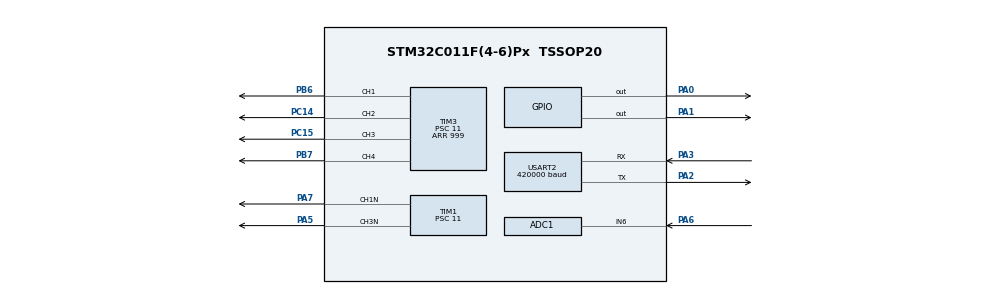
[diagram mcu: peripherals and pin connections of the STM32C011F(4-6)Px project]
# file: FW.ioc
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ADC1.NbrOfConversionFlag=0
ADC1.SamplingTimeCommon1=ADC_SAMPLETIME_12CYCLES_5
ADC1.SelectedChannel=ADC_CHANNEL_6
ADC1.master=1
Mcu.Family=STM32C0
Mcu.Name=STM32C011F(4-6)Px
Mcu.Package=TSSOP20
NVIC.USART2_IRQn=true\:0\:0\:false\:false\:true\:true\:true\:true
PA0.Signal=GPIO_Output
PA1.Signal=GPIO_Output
PA13.Mode=Serial_Wire
PA13.Signal=DEBUG_SWDIO
PA14-BOOT0.Mode=Serial_Wire
PA14-BOOT0.Signal=DEBUG_SWCLK
PA2.Mode=Asynchronous
PA2.Signal=USART2_TX
PA3.Mode=Asynchronous
PA3.Signal=USART2_RX
PA5.Mode=PWM Generation3 CH3N
PA5.Signal=TIM1_CH3N
PA6.Mode=IN6
PA6.Signal=ADC1_IN6
PA7.Mode=PWM Generation1 CH1N
PA7.Signal=TIM1_CH1N
PB6.Signal=S_TIM3_CH1
PB7.Signal=S_TIM3_CH4
PC14-OSCX_IN\ (PC14).Signal=S_TIM3_CH2
PC15-OSCX_OUT\ (PC15).Signal=S_TIM3_CH3
PF2-NRST.Signal=S_TIM1_CH4
ProjectManager.HeapSize=0x200
ProjectManager.StackSize=0x400
ProjectManager.TargetToolchain=STM32CubeIDE
RCC.ADCFreq_Value=48000000
RCC.AHBFreq_Value=48000000
RCC.CortexFreq_Value=48000000
RCC.EXTERNAL_CLOCK_VALUE=12288000
RCC.HCLKFreq_Value=48000000
RCC.HSE_VALUE=8000000
RCC.HSISYSCLKDivider=RCC_HSI_DIV1
RCC.HSI_VALUE=48000000
RCC.LSE_VALUE=32768
RCC.SYSCLKFreq_VALUE=48000000
SH.S_TIM1_CH4.0=TIM1_CH4
SH.S_TIM3_CH1.0=TIM3_CH1,PWM Generation1 CH1
SH.S_TIM3_CH2.0=TIM3_CH2,PWM Generation2 CH2
SH.S_TIM3_CH3.0=TIM3_CH3,PWM Generation3 CH3
SH.S_TIM3_CH4.0=TIM3_CH4,PWM Generation4 CH4
TIM1.Channel-PWM\ Generation1\ CH1N=TIM_CHANNEL_1
TIM1.Channel-PWM\ Generation3\ CH3N=TIM_CHANNEL_3
TIM1.Period=999
TIM1.Prescaler=11
TIM3.Channel-PWM\ Generation1\ CH1=TIM_CHANNEL_1
TIM3.Channel-PWM\ Generation2\ CH2=TIM_CHANNEL_2
TIM3.Channel-PWM\ Generation3\ CH3=TIM_CHANNEL_3
TIM3.Channel-PWM\ Generation4\ CH4=TIM_CHANNEL_4
TIM3.Period=999
TIM3.Prescaler=11
USART2.BaudRate=420000
USART2.DMADisableonRxErrorParam=ADVFEATURE_DMA_DISABLEONRXERROR
USART2.OverrunDisableParam=ADVFEATURE_OVERRUN_DISABLE
USART2.VirtualMode-Asynchronous=VM_ASYNC
VP_CRC_VS_CRC.Mode=CRC_Activate
VP_SYS_VS_PINREMAP.Mode=PINREMAP
VP_SYS_VS_PINREMAP_10_12.Mode=PINREMAP_10_12
VP_TIM1_VS_ClockSourceINT.Mode=Internal
VP_TIM3_VS_ClockSourceINT.Mode=Internal
board=custom

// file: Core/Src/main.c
/* USER CODE BEGIN Header */
/**
  ******************************************************************************
  * @file           : main.c
  * @brief          : Main program body
  ******************************************************************************
  * @attention
  *
  * Copyright (c) 2026 STMicroelectronics.
  * All rights reserved.
  *
  * This software is licensed under terms that can be found in the LICENSE file
  * in the root directory of this software component.
  * If no LICENSE file comes with this software, it is provided AS-IS.
  *
  ******************************************************************************
  */
/* USER CODE END Header */
#include "main.h"

/* USER CODE BEGIN Includes */
#include "crsf_esc.h"
/* USER CODE END Includes */

void SystemClock_Config(void);
static void MX_GPIO_Init(void);
static void MX_TIM1_Init(void);
static void MX_TIM3_Init(void);
static void MX_USART2_UART_Init(void);
static void MX_ADC1_Init(void);
static void MX_CRC_Init(void);

int main(void)
{

  /* MCU Configuration--------------------------------------------------------*/

  /* Reset of all peripherals, Initializes the Flash interface and the Systick. */
  LL_APB2_GRP1_EnableClock(LL_APB2_GRP1_PERIPH_SYSCFG);
  LL_APB1_GRP1_EnableClock(LL_APB1_GRP1_PERIPH_PWR);

  /* SysTick_IRQn interrupt configuration */
  NVIC_SetPriority(SysTick_IRQn, 3);

  LL_SYSCFG_EnablePinRemap(LL_SYSCFG_PIN_RMP_PA11);
  LL_SYSCFG_EnablePinRemap(LL_SYSCFG_PIN_RMP_PA12);

  /* Configure the system clock */
  SystemClock_Config();

  /* Initialize all configured peripherals */
  MX_GPIO_Init();
  MX_TIM1_Init();
  MX_TIM3_Init();
  MX_USART2_UART_Init();
  MX_ADC1_Init();
  MX_CRC_Init();
  /* USER CODE BEGIN 2 */
  esc_main();
  /* USER CODE END 2 */

  /* Infinite loop */
  while (1)
  {

  }
}

void SystemClock_Config(void)
{

  LL_FLASH_SetLatency(LL_FLASH_LATENCY_1);

  /* HSI configuration and activation */
  LL_RCC_HSI_Enable();
  while(LL_RCC_HSI_IsReady() != 1)
  {
  }

  LL_RCC_HSI_SetCalibTrimming(64);
  LL_RCC_SetHSIDiv(LL_RCC_HSI_DIV_1);
  /* Set AHB prescaler*/
  LL_RCC_SetAHBPrescaler(LL_RCC_HCLK_DIV_1);

  /* Sysclk activation on the HSI */
  LL_RCC_SetSysClkSource(LL_RCC_SYS_CLKSOURCE_HSI);
  while(LL_RCC_GetSysClkSource() != LL_RCC_SYS_CLKSOURCE_STATUS_HSI)
  {
  }

  /* Set APB1 prescaler*/
  LL_RCC_SetAPB1Prescaler(LL_RCC_APB1_DIV_1);
  LL_Init1msTick(48000000);
  /* Update CMSIS variable (which can be updated also through SystemCoreClockUpdate function) */
  LL_SetSystemCoreClock(48000000);
}

static void MX_ADC1_Init(void)
{

  LL_ADC_InitTypeDef ADC_InitStruct = {0};
  LL_ADC_REG_InitTypeDef ADC_REG_InitStruct = {0};

  LL_GPIO_InitTypeDef GPIO_InitStruct = {0};

  LL_RCC_SetADCClockSource(LL_RCC_ADC_CLKSOURCE_SYSCLK);

  /* Peripheral clock enable */
  LL_APB2_GRP1_EnableClock(LL_APB2_GRP1_PERIPH_ADC);

  LL_IOP_GRP1_EnableClock(LL_IOP_GRP1_PERIPH_GPIOA);
  /**ADC1 GPIO Configuration
  PA6   ------> ADC1_IN6
  */
  GPIO_InitStruct.Pin = LL_GPIO_PIN_6;
  GPIO_InitStruct.Mode = LL_GPIO_MODE_ANALOG;
  GPIO_InitStruct.Pull = LL_GPIO_PULL_NO;
  LL_GPIO_Init(GPIOA, &GPIO_InitStruct);

  /** Configure the global features of the ADC (Clock, Resolution, Data Alignment and number of conversion)
  */

   #define ADC_CHANNEL_CONF_RDY_TIMEOUT_MS ( 1U)
   #if (USE_TIMEOUT == 1)
   uint32_t Timeout ; /* Variable used for Timeout management */
   #endif /* USE_TIMEOUT */

  ADC_InitStruct.Clock = LL_ADC_CLOCK_SYNC_PCLK_DIV2;
  ADC_InitStruct.Resolution = LL_ADC_RESOLUTION_12B;
  ADC_InitStruct.DataAlignment = LL_ADC_DATA_ALIGN_RIGHT;
  ADC_InitStruct.LowPowerMode = LL_ADC_LP_MODE_NONE;
  LL_ADC_Init(ADC1, &ADC_InitStruct);
  LL_ADC_REG_SetSequencerConfigurable(ADC1, LL_ADC_REG_SEQ_FIXED);
  ADC_REG_InitStruct.TriggerSource = LL_ADC_REG_TRIG_SOFTWARE;
  ADC_REG_InitStruct.SequencerLength = LL_ADC_REG_SEQ_SCAN_DISABLE;
  ADC_REG_InitStruct.SequencerDiscont = LL_ADC_REG_SEQ_DISCONT_DISABLE;
  ADC_REG_InitStruct.ContinuousMode = LL_ADC_REG_CONV_SINGLE;
  ADC_REG_InitStruct.DMATransfer = LL_ADC_REG_DMA_TRANSFER_NONE;
  ADC_REG_InitStruct.Overrun = LL_ADC_REG_OVR_DATA_PRESERVED;
  LL_ADC_REG_Init(ADC1, &ADC_REG_InitStruct);
  LL_ADC_REG_SetSequencerScanDirection(ADC1, LL_ADC_REG_SEQ_SCAN_DIR_FORWARD);
  LL_ADC_SetOverSamplingScope(ADC1, LL_ADC_OVS_DISABLE);
  LL_ADC_SetTriggerFrequencyMode(ADC1, LL_ADC_CLOCK_FREQ_MODE_HIGH);
  LL_ADC_REG_SetSequencerChAdd(ADC1, LL_ADC_CHANNEL_6);

   /* Poll for ADC channel configuration ready */
   #if (USE_TIMEOUT == 1)
   Timeout = ADC_CHANNEL_CONF_RDY_TIMEOUT_MS;
   #endif /* USE_TIMEOUT */
   while (LL_ADC_IsActiveFlag_CCRDY(ADC1) == 0)
     {
   #if (USE_TIMEOUT == 1)
   /* Check Systick counter flag to decrement the time-out value */
   if (LL_SYSTICK_IsActiveCounterFlag())
     {
   if(Timeout-- == 0)
         {
   Error_Handler();
         }
     }
   #endif /* USE_TIMEOUT */
     }
   /* Clear flag ADC channel configuration ready */
   LL_ADC_ClearFlag_CCRDY(ADC1);
  LL_ADC_SetSamplingTimeCommonChannels(ADC1, LL_ADC_SAMPLINGTIME_COMMON_1, LL_ADC_SAMPLINGTIME_12CYCLES_5);
  LL_ADC_DisableIT_EOC(ADC1);
  LL_ADC_DisableIT_EOS(ADC1);

   /* Enable ADC internal voltage regulator */
   LL_ADC_EnableInternalRegulator(ADC1);
   /* Delay for ADC internal voltage regulator stabilization. */
   /* Compute number of CPU cycles to wait for, from delay in us. */
   /* Note: Variable divided by 2 to compensate partially */
   /* CPU processing cycles (depends on compilation optimization). */
   /* Note: If system core clock frequency is below 200kHz, wait time */
   /* is only a few CPU processing cycles. */
   uint32_t wait_loop_index;
   wait_loop_index = ((LL_ADC_DELAY_INTERNAL_REGUL_STAB_US * (SystemCoreClock / (100000 * 2))) / 10);
   while(wait_loop_index != 0)
     {
   wait_loop_index--;
     }

}

static void MX_CRC_Init(void)
{

  /* Peripheral clock enable */
  LL_AHB1_GRP1_EnableClock(LL_AHB1_GRP1_PERIPH_CRC);

  LL_CRC_SetInputDataReverseMode(CRC, LL_CRC_INDATA_REVERSE_NONE);
  LL_CRC_SetOutputDataReverseMode(CRC, LL_CRC_OUTDATA_REVERSE_NONE);
  LL_CRC_SetPolynomialCoef(CRC, LL_CRC_DEFAULT_CRC32_POLY);
  LL_CRC_SetPolynomialSize(CRC, LL_CRC_POLYLENGTH_32B);
  LL_CRC_SetInitialData(CRC, LL_CRC_DEFAULT_CRC_INITVALUE);

}

static void MX_TIM1_Init(void)
{

  LL_TIM_InitTypeDef TIM_InitStruct = {0};
  LL_TIM_OC_InitTypeDef TIM_OC_InitStruct = {0};
  LL_TIM_BDTR_InitTypeDef TIM_BDTRInitStruct = {0};

  LL_GPIO_InitTypeDef GPIO_InitStruct = {0};

  /* Peripheral clock enable */
  LL_APB2_GRP1_EnableClock(LL_APB2_GRP1_PERIPH_TIM1);

  LL_IOP_GRP1_EnableClock(LL_IOP_GRP1_PERIPH_GPIOF);
  /**TIM1 GPIO Configuration
  PF2-NRST   ------> TIM1_CH4
  */
  GPIO_InitStruct.Pin = LL_GPIO_PIN_2;
  GPIO_InitStruct.Mode = LL_GPIO_MODE_ALTERNATE;
  GPIO_InitStruct.Speed = LL_GPIO_SPEED_FREQ_LOW;
  GPIO_InitStruct.OutputType = LL_GPIO_OUTPUT_PUSHPULL;
  GPIO_InitStruct.Pull = LL_GPIO_PULL_NO;
  GPIO_InitStruct.Alternate = LL_GPIO_AF_1;
  LL_GPIO_Init(GPIOF, &GPIO_InitStruct);

  TIM_InitStruct.Prescaler = 11;
  TIM_InitStruct.CounterMode = LL_TIM_COUNTERMODE_UP;
  TIM_InitStruct.Autoreload = 999;
  TIM_InitStruct.ClockDivision = LL_TIM_CLOCKDIVISION_DIV1;
  TIM_InitStruct.RepetitionCounter = 0;
  LL_TIM_Init(TIM1, &TIM_InitStruct);
  LL_TIM_DisableARRPreload(TIM1);
  LL_TIM_SetClockSource(TIM1, LL_TIM_CLOCKSOURCE_INTERNAL);
  LL_TIM_OC_EnablePreload(TIM1, LL_TIM_CHANNEL_CH1);
  TIM_OC_InitStruct.OCMode = LL_TIM_OCMODE_PWM1;
  TIM_OC_InitStruct.OCState = LL_TIM_OCSTATE_DISABLE;
  TIM_OC_InitStruct.OCNState = LL_TIM_OCSTATE_DISABLE;
  TIM_OC_InitStruct.CompareValue = 0;
  TIM_OC_InitStruct.OCPolarity = LL_TIM_OCPOLARITY_HIGH;
  TIM_OC_InitStruct.OCNPolarity = LL_TIM_OCPOLARITY_HIGH;
  TIM_OC_InitStruct.OCIdleState = LL_TIM_OCIDLESTATE_LOW;
  TIM_OC_InitStruct.OCNIdleState = LL_TIM_OCIDLESTATE_LOW;
  LL_TIM_OC_Init(TIM1, LL_TIM_CHANNEL_CH1, &TIM_OC_InitStruct);
  LL_TIM_OC_DisableFast(TIM1, LL_TIM_CHANNEL_CH1);
  LL_TIM_OC_EnablePreload(TIM1, LL_TIM_CHANNEL_CH3);
  LL_TIM_OC_Init(TIM1, LL_TIM_CHANNEL_CH3, &TIM_OC_InitStruct);
  LL_TIM_OC_DisableFast(TIM1, LL_TIM_CHANNEL_CH3);
  LL_TIM_SetTriggerOutput(TIM1, LL_TIM_TRGO_RESET);
  LL_TIM_SetTriggerOutput2(TIM1, LL_TIM_TRGO2_RESET);
  LL_TIM_DisableMasterSlaveMode(TIM1);
  TIM_BDTRInitStruct.OSSRState = LL_TIM_OSSR_DISABLE;
  TIM_BDTRInitStruct.OSSIState = LL_TIM_OSSI_DISABLE;
  TIM_BDTRInitStruct.LockLevel = LL_TIM_LOCKLEVEL_OFF;
  TIM_BDTRInitStruct.DeadTime = 0;
  TIM_BDTRInitStruct.BreakState = LL_TIM_BREAK_DISABLE;
  TIM_BDTRInitStruct.BreakPolarity = LL_TIM_BREAK_POLARITY_HIGH;
  TIM_BDTRInitStruct.BreakFilter = LL_TIM_BREAK_FILTER_FDIV1;
  TIM_BDTRInitStruct.BreakAFMode = LL_TIM_BREAK_AFMODE_INPUT;
  TIM_BDTRInitStruct.Break2State = LL_TIM_BREAK2_DISABLE;
  TIM_BDTRInitStruct.Break2Polarity = LL_TIM_BREAK2_POLARITY_HIGH;
  TIM_BDTRInitStruct.Break2Filter = LL_TIM_BREAK2_FILTER_FDIV1;
  TIM_BDTRInitStruct.Break2AFMode = LL_TIM_BREAK_AFMODE_INPUT;
  TIM_BDTRInitStruct.AutomaticOutput = LL_TIM_AUTOMATICOUTPUT_DISABLE;
  LL_TIM_BDTR_Init(TIM1, &TIM_BDTRInitStruct);
  LL_IOP_GRP1_EnableClock(LL_IOP_GRP1_PERIPH_GPIOA);
  /**TIM1 GPIO Configuration
  PA5   ------> TIM1_CH3N
  PA7   ------> TIM1_CH1N
  */
  GPIO_InitStruct.Pin = LL_GPIO_PIN_5;
  GPIO_InitStruct.Mode = LL_GPIO_MODE_ALTERNATE;
  GPIO_InitStruct.Speed = LL_GPIO_SPEED_FREQ_LOW;
  GPIO_InitStruct.OutputType = LL_GPIO_OUTPUT_PUSHPULL;
  GPIO_InitStruct.Pull = LL_GPIO_PULL_NO;
  GPIO_InitStruct.Alternate = LL_GPIO_AF_2;
  LL_GPIO_Init(GPIOA, &GPIO_InitStruct);

  GPIO_InitStruct.Pin = LL_GPIO_PIN_7;
  GPIO_InitStruct.Mode = LL_GPIO_MODE_ALTERNATE;
  GPIO_InitStruct.Speed = LL_GPIO_SPEED_FREQ_LOW;
  GPIO_InitStruct.OutputType = LL_GPIO_OUTPUT_PUSHPULL;
  GPIO_InitStruct.Pull = LL_GPIO_PULL_NO;
  GPIO_InitStruct.Alternate = LL_GPIO_AF_2;
  LL_GPIO_Init(GPIOA, &GPIO_InitStruct);

}

static void MX_TIM3_Init(void)
{

  LL_TIM_InitTypeDef TIM_InitStruct = {0};
  LL_TIM_OC_InitTypeDef TIM_OC_InitStruct = {0};

  LL_GPIO_InitTypeDef GPIO_InitStruct = {0};

  /* Peripheral clock enable */
  LL_APB1_GRP1_EnableClock(LL_APB1_GRP1_PERIPH_TIM3);

  TIM_InitStruct.Prescaler = 11;
  TIM_InitStruct.CounterMode = LL_TIM_COUNTERMODE_UP;
  TIM_InitStruct.Autoreload = 999;
  TIM_InitStruct.ClockDivision = LL_TIM_CLOCKDIVISION_DIV1;
  LL_TIM_Init(TIM3, &TIM_InitStruct);
  LL_TIM_DisableARRPreload(TIM3);
  LL_TIM_SetClockSource(TIM3, LL_TIM_CLOCKSOURCE_INTERNAL);
  LL_TIM_OC_EnablePreload(TIM3, LL_TIM_CHANNEL_CH1);
  TIM_OC_InitStruct.OCMode = LL_TIM_OCMODE_PWM1;
  TIM_OC_InitStruct.OCState = LL_TIM_OCSTATE_DISABLE;
  TIM_OC_InitStruct.OCNState = LL_TIM_OCSTATE_DISABLE;
  TIM_OC_InitStruct.CompareValue = 0;
  TIM_OC_InitStruct.OCPolarity = LL_TIM_OCPOLARITY_HIGH;
  LL_TIM_OC_Init(TIM3, LL_TIM_CHANNEL_CH1, &TIM_OC_InitStruct);
  LL_TIM_OC_DisableFast(TIM3, LL_TIM_CHANNEL_CH1);
  LL_TIM_OC_EnablePreload(TIM3, LL_TIM_CHANNEL_CH2);
  LL_TIM_OC_Init(TIM3, LL_TIM_CHANNEL_CH2, &TIM_OC_InitStruct);
  LL_TIM_OC_DisableFast(TIM3, LL_TIM_CHANNEL_CH2);
  LL_TIM_OC_EnablePreload(TIM3, LL_TIM_CHANNEL_CH3);
  LL_TIM_OC_Init(TIM3, LL_TIM_CHANNEL_CH3, &TIM_OC_InitStruct);
  LL_TIM_OC_DisableFast(TIM3, LL_TIM_CHANNEL_CH3);
  LL_TIM_OC_EnablePreload(TIM3, LL_TIM_CHANNEL_CH4);
  LL_TIM_OC_Init(TIM3, LL_TIM_CHANNEL_CH4, &TIM_OC_InitStruct);
  LL_TIM_OC_DisableFast(TIM3, LL_TIM_CHANNEL_CH4);
  LL_TIM_SetTriggerOutput(TIM3, LL_TIM_TRGO_RESET);
  LL_TIM_DisableMasterSlaveMode(TIM3);
  LL_IOP_GRP1_EnableClock(LL_IOP_GRP1_PERIPH_GPIOB);
  LL_IOP_GRP1_EnableClock(LL_IOP_GRP1_PERIPH_GPIOC);
  /**TIM3 GPIO Configuration
  PB7   ------> TIM3_CH4
  PC14-OSCX_IN (PC14)   ------> TIM3_CH2
  PC15-OSCX_OUT (PC15)   ------> TIM3_CH3
  PB6   ------> TIM3_CH1
  */
  GPIO_InitStruct.Pin = LL_GPIO_PIN_7;
  GPIO_InitStruct.Mode = LL_GPIO_MODE_ALTERNATE;
  GPIO_InitStruct.Speed = LL_GPIO_SPEED_FREQ_LOW;
  GPIO_InitStruct.OutputType = LL_GPIO_OUTPUT_PUSHPULL;
  GPIO_InitStruct.Pull = LL_GPIO_PULL_NO;
  GPIO_InitStruct.Alternate = LL_GPIO_AF_3;
  LL_GPIO_Init(GPIOB, &GPIO_InitStruct);

  GPIO_InitStruct.Pin = LL_GPIO_PIN_14;
  GPIO_InitStruct.Mode = LL_GPIO_MODE_ALTERNATE;
  GPIO_InitStruct.Speed = LL_GPIO_SPEED_FREQ_LOW;
  GPIO_InitStruct.OutputType = LL_GPIO_OUTPUT_PUSHPULL;
  GPIO_InitStruct.Pull = LL_GPIO_PULL_NO;
  GPIO_InitStruct.Alternate = LL_GPIO_AF_11;
  LL_GPIO_Init(GPIOC, &GPIO_InitStruct);

  GPIO_InitStruct.Pin = LL_GPIO_PIN_15;
  GPIO_InitStruct.Mode = LL_GPIO_MODE_ALTERNATE;
  GPIO_InitStruct.Speed = LL_GPIO_SPEED_FREQ_LOW;
  GPIO_InitStruct.OutputType = LL_GPIO_OUTPUT_PUSHPULL;
  GPIO_InitStruct.Pull = LL_GPIO_PULL_NO;
  GPIO_InitStruct.Alternate = LL_GPIO_AF_3;
  LL_GPIO_Init(GPIOC, &GPIO_InitStruct);

  GPIO_InitStruct.Pin = LL_GPIO_PIN_6;
  GPIO_InitStruct.Mode = LL_GPIO_MODE_ALTERNATE;
  GPIO_InitStruct.Speed = LL_GPIO_SPEED_FREQ_LOW;
  GPIO_InitStruct.OutputType = LL_GPIO_OUTPUT_PUSHPULL;
  GPIO_InitStruct.Pull = LL_GPIO_PULL_NO;
  GPIO_InitStruct.Alternate = LL_GPIO_AF_12;
  LL_GPIO_Init(GPIOB, &GPIO_InitStruct);

}

static void MX_USART2_UART_Init(void)
{

  LL_USART_InitTypeDef USART_InitStruct = {0};

  LL_GPIO_InitTypeDef GPIO_InitStruct = {0};

  /* Peripheral clock enable */
  LL_APB1_GRP1_EnableClock(LL_APB1_GRP1_PERIPH_USART2);

  LL_IOP_GRP1_EnableClock(LL_IOP_GRP1_PERIPH_GPIOA);
  /**USART2 GPIO Configuration
  PA2   ------> USART2_TX
  PA3   ------> USART2_RX
  */
  GPIO_InitStruct.Pin = LL_GPIO_PIN_2;
  GPIO_InitStruct.Mode = LL_GPIO_MODE_ALTERNATE;
  GPIO_InitStruct.Speed = LL_GPIO_SPEED_FREQ_LOW;
  GPIO_InitStruct.OutputType = LL_GPIO_OUTPUT_PUSHPULL;
  GPIO_InitStruct.Pull = LL_GPIO_PULL_NO;
  GPIO_InitStruct.Alternate = LL_GPIO_AF_1;
  LL_GPIO_Init(GPIOA, &GPIO_InitStruct);

  GPIO_InitStruct.Pin = LL_GPIO_PIN_3;
  GPIO_InitStruct.Mode = LL_GPIO_MODE_ALTERNATE;
  GPIO_InitStruct.Speed = LL_GPIO_SPEED_FREQ_LOW;
  GPIO_InitStruct.OutputType = LL_GPIO_OUTPUT_PUSHPULL;
  GPIO_InitStruct.Pull = LL_GPIO_PULL_NO;
  GPIO_InitStruct.Alternate = LL_GPIO_AF_1;
  LL_GPIO_Init(GPIOA, &GPIO_InitStruct);

  /* USART2 interrupt Init */
  NVIC_SetPriority(USART2_IRQn, 0);
  NVIC_EnableIRQ(USART2_IRQn);

  USART_InitStruct.PrescalerValue = LL_USART_PRESCALER_DIV1;
  USART_InitStruct.BaudRate = 420000;
  USART_InitStruct.DataWidth = LL_USART_DATAWIDTH_8B;
  USART_InitStruct.StopBits = LL_USART_STOPBITS_1;
  USART_InitStruct.Parity = LL_USART_PARITY_NONE;
  USART_InitStruct.TransferDirection = LL_USART_DIRECTION_TX_RX;
  USART_InitStruct.HardwareFlowControl = LL_USART_HWCONTROL_NONE;
  USART_InitStruct.OverSampling = LL_USART_OVERSAMPLING_16;
  LL_USART_Init(USART2, &USART_InitStruct);
  LL_USART_DisableOverrunDetect(USART2);
  LL_USART_DisableDMADeactOnRxErr(USART2);
  LL_USART_ConfigAsyncMode(USART2);

  LL_USART_Enable(USART2);

  /* Polling USART2 initialisation */
  while((!(LL_USART_IsActiveFlag_TEACK(USART2))) || (!(LL_USART_IsActiveFlag_REACK(USART2))))
  {
  }

}

static void MX_GPIO_Init(void)
{
  LL_GPIO_InitTypeDef GPIO_InitStruct = {0};

  /* GPIO Ports Clock Enable */
  LL_IOP_GRP1_EnableClock(LL_IOP_GRP1_PERIPH_GPIOB);
  LL_IOP_GRP1_EnableClock(LL_IOP_GRP1_PERIPH_GPIOC);
  LL_IOP_GRP1_EnableClock(LL_IOP_GRP1_PERIPH_GPIOF);
  LL_IOP_GRP1_EnableClock(LL_IOP_GRP1_PERIPH_GPIOA);

  /**/
  LL_GPIO_ResetOutputPin(GPIOA, LL_GPIO_PIN_0);

  /**/
  LL_GPIO_ResetOutputPin(GPIOA, LL_GPIO_PIN_1);

  /**/
  GPIO_InitStruct.Pin = LL_GPIO_PIN_0;
  GPIO_InitStruct.Mode = LL_GPIO_MODE_OUTPUT;
  GPIO_InitStruct.Speed = LL_GPIO_SPEED_FREQ_LOW;
  GPIO_InitStruct.OutputType = LL_GPIO_OUTPUT_PUSHPULL;
  GPIO_InitStruct.Pull = LL_GPIO_PULL_NO;
  LL_GPIO_Init(GPIOA, &GPIO_InitStruct);

  /**/
  GPIO_InitStruct.Pin = LL_GPIO_PIN_1;
  GPIO_InitStruct.Mode = LL_GPIO_MODE_OUTPUT;
  GPIO_InitStruct.Speed = LL_GPIO_SPEED_FREQ_LOW;
  GPIO_InitStruct.OutputType = LL_GPIO_OUTPUT_PUSHPULL;
  GPIO_InitStruct.Pull = LL_GPIO_PULL_NO;
  LL_GPIO_Init(GPIOA, &GPIO_InitStruct);

}

void Error_Handler(void)
{
  __disable_irq();
  while (1)
  {
  }
}
